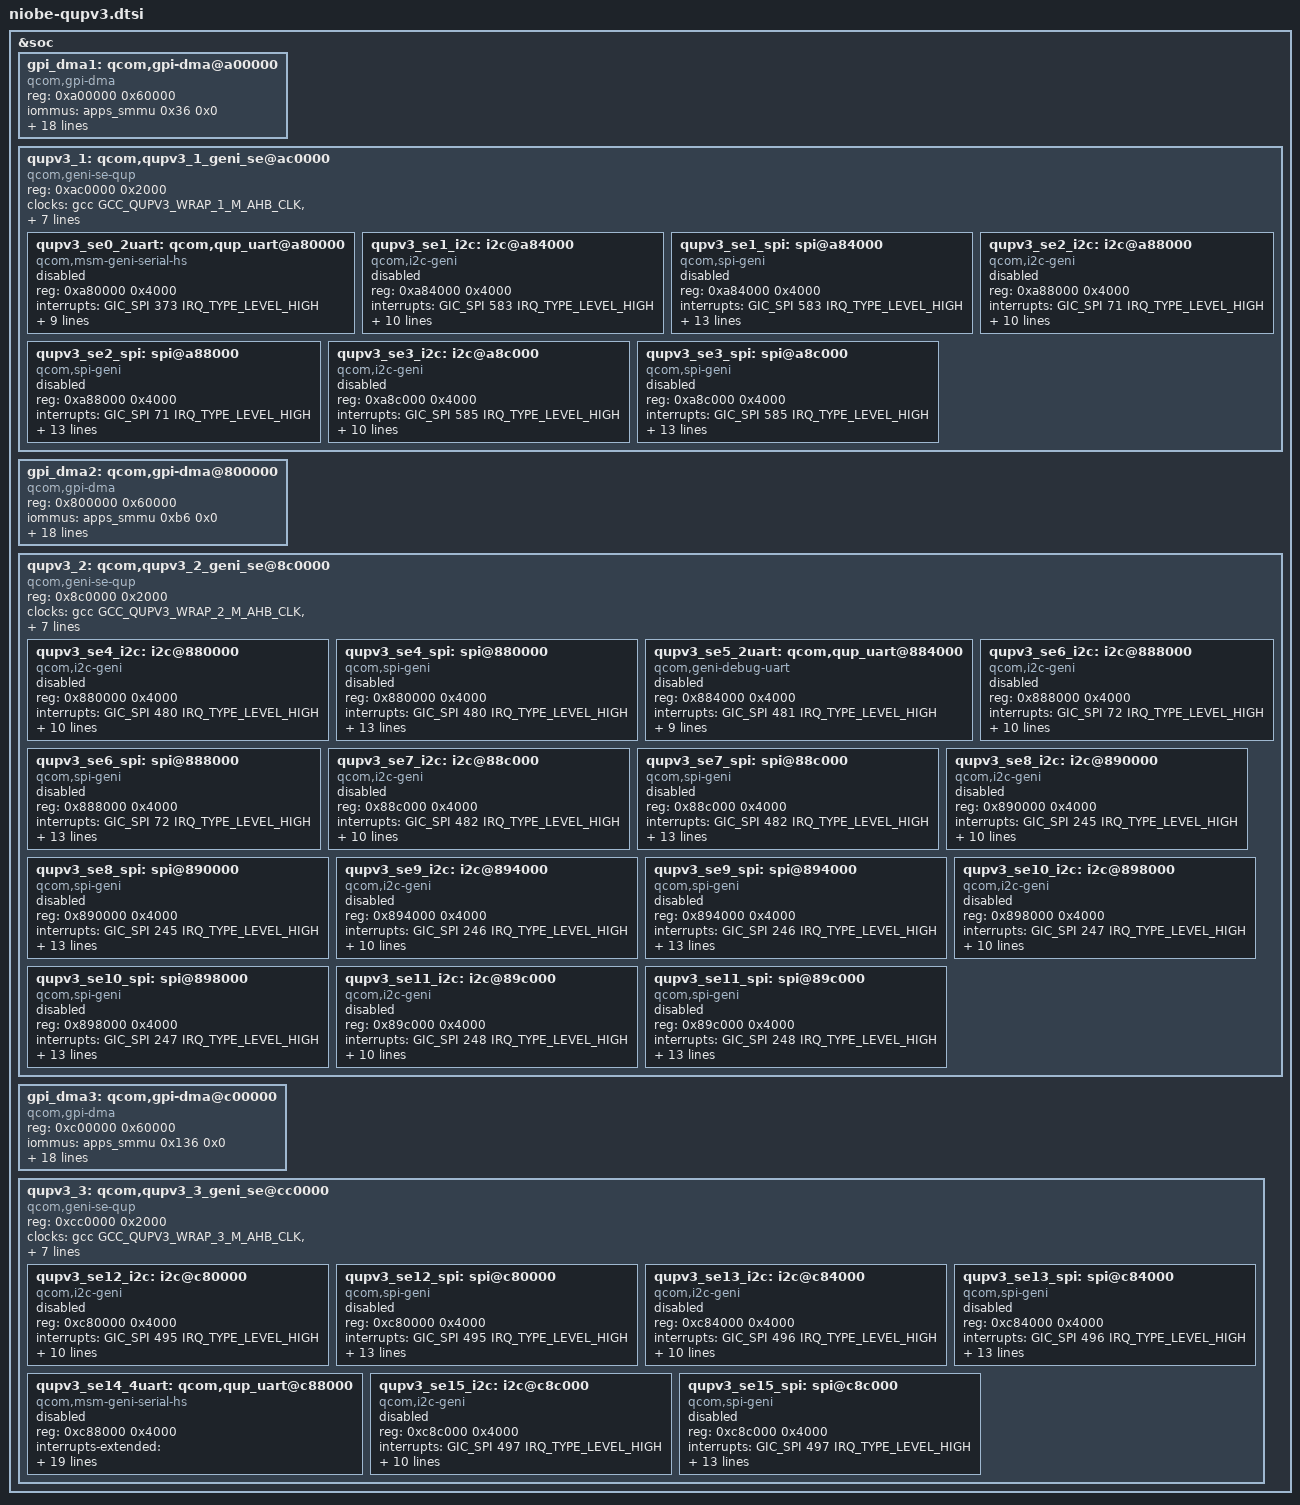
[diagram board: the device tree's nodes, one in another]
&soc {
	/* QUPv3 SE Instances
	 * Qup1 0: SE 0
	 * Qup1 1: SE 1
	 * Qup1 2: SE 2
	 * Qup1 3: SE 3
	 * Qup2 0: SE 4
	 * Qup2 1: SE 5
	 * Qup2 2: SE 6
	 * Qup2 3: SE 7
	 * Qup2 4: SE 8
	 * Qup2 5: SE 9
	 * Qup2 6: SE 10
	 * Qup2 7: SE 11
	 * Qup3 0: SE 12
	 * Qup3 1: SE 13
	 * Qup3 2: SE 14
	 * Qup3 3: SE 15
	 */

	/* GPI Instance */
	gpi_dma1: qcom,gpi-dma@a00000 {
		compatible = "qcom,gpi-dma";
		#dma-cells = <5>;
		reg = <0xa00000 0x60000>;
		reg-names = "gpi-top";
		iommus = <&apps_smmu 0x36 0x0>;
		qcom,max-num-gpii = <12>;
		interrupts = <GIC_SPI 588 IRQ_TYPE_LEVEL_HIGH>,
			<GIC_SPI 589 IRQ_TYPE_LEVEL_HIGH>,
			<GIC_SPI 590 IRQ_TYPE_LEVEL_HIGH>,
			<GIC_SPI 591 IRQ_TYPE_LEVEL_HIGH>,
			<GIC_SPI 592 IRQ_TYPE_LEVEL_HIGH>,
			<GIC_SPI 593 IRQ_TYPE_LEVEL_HIGH>,
			<GIC_SPI 594 IRQ_TYPE_LEVEL_HIGH>,
			<GIC_SPI 595 IRQ_TYPE_LEVEL_HIGH>,
			<GIC_SPI 596 IRQ_TYPE_LEVEL_HIGH>,
			<GIC_SPI 597 IRQ_TYPE_LEVEL_HIGH>,
			<GIC_SPI 598 IRQ_TYPE_LEVEL_HIGH>,
			<GIC_SPI 599 IRQ_TYPE_LEVEL_HIGH>;
		qcom,gpii-mask = <0x3f>;
		qcom,ev-factor = <1>;
		qcom,iommu-dma-addr-pool = <0x100000 0x100000>;
		qcom,gpi-ee-offset = <0x10000>;
		dma-coherent;
		status = "ok";
	};

	/* QUPv3_1  wrapper  instance */
	qupv3_1: qcom,qupv3_1_geni_se@ac0000 {
		compatible = "qcom,geni-se-qup";
		reg = <0xac0000 0x2000>;
		#address-cells = <1>;
		#size-cells = <1>;
		clock-names = "m-ahb", "s-ahb";
		clocks = <&gcc GCC_QUPV3_WRAP_1_M_AHB_CLK>,
			<&gcc GCC_QUPV3_WRAP_1_S_AHB_CLK>;
		iommus = <&apps_smmu 0x23 0x0>;
		qcom,iommu-dma-addr-pool = <0x40000000 0x10000000>;
		qcom,iommu-geometry = <0x40000000 0x10000000>;
		qcom,iommu-dma = "fastmap";
		dma-coherent;
		ranges;
		status = "ok";

		/* Nordic BT UART Instance */
		qupv3_se0_2uart: qcom,qup_uart@a80000 {
			compatible = "qcom,msm-geni-serial-hs";
			reg = <0xa80000 0x4000>;
			reg-names = "se_phys";
			interrupts = <GIC_SPI 373 IRQ_TYPE_LEVEL_HIGH>;
			clock-names = "se-clk";
			clocks = <&gcc GCC_QUPV3_WRAP1_S0_CLK>;
			interconnect-names = "qup-core", "qup-config", "qup-memory";
			interconnects =
			<&clk_virt MASTER_QUP_CORE_1 &clk_virt SLAVE_QUP_CORE_1>,
			<&gem_noc MASTER_APPSS_PROC &cnoc_cfg SLAVE_QUP_1>,
			<&aggre1_noc MASTER_QUP_1 &mc_virt SLAVE_EBI1>;
			pinctrl-names = "default", "sleep";
			pinctrl-0 = <&qupv3_se0_2uart_tx_active>, <&qupv3_se0_2uart_rx_active>;
			pinctrl-1 = <&qupv3_se0_2uart_sleep>;
			status = "disabled";
		};

		qupv3_se1_i2c: i2c@a84000 {
			compatible = "qcom,i2c-geni";
			reg = <0xa84000 0x4000>;
			#address-cells = <1>;
			#size-cells = <0>;
			interrupts = <GIC_SPI 583 IRQ_TYPE_LEVEL_HIGH>;
			clock-names = "se-clk";
			clocks = <&gcc GCC_QUPV3_WRAP1_S1_CLK>;
			interconnect-names = "qup-core", "qup-config", "qup-memory";
			interconnects =
			<&clk_virt MASTER_QUP_CORE_1 &clk_virt SLAVE_QUP_CORE_1>,
			<&gem_noc MASTER_APPSS_PROC &cnoc_cfg SLAVE_QUP_1>,
			<&aggre1_noc MASTER_QUP_1 &mc_virt SLAVE_EBI1>;
			pinctrl-names = "default", "sleep";
			pinctrl-0 = <&qupv3_se1_i2c_sda_active>, <&qupv3_se1_i2c_scl_active>;
			pinctrl-1 = <&qupv3_se1_i2c_sleep>;
			dmas = <&gpi_dma1 0 1 3 64 0>,
				<&gpi_dma1 1 1 3 64 0>;
			dma-names = "tx", "rx";
			status = "disabled";
		};

		qupv3_se1_spi: spi@a84000 {
			compatible = "qcom,spi-geni";
			reg = <0xa84000 0x4000>;
			#address-cells = <1>;
			#size-cells = <0>;
			reg-names = "se_phys";
			interrupts = <GIC_SPI 583 IRQ_TYPE_LEVEL_HIGH>;
			clock-names = "se-clk";
			clocks = <&gcc GCC_QUPV3_WRAP1_S1_CLK>;
			interconnect-names = "qup-core", "qup-config", "qup-memory";
			interconnects =
			<&clk_virt MASTER_QUP_CORE_1 &clk_virt SLAVE_QUP_CORE_1>,
			<&gem_noc MASTER_APPSS_PROC &cnoc_cfg SLAVE_QUP_1>,
			<&aggre1_noc MASTER_QUP_1 &mc_virt SLAVE_EBI1>;
			pinctrl-names = "default", "sleep";
			pinctrl-0 = <&qupv3_se1_spi_mosi_active>, <&qupv3_se1_spi_miso_active>,
				<&qupv3_se1_spi_clk_active>, <&qupv3_se1_spi_cs_active>;
			pinctrl-1 = <&qupv3_se1_spi_sleep>;
			dmas = <&gpi_dma1 0 1 1 64 0>,
				<&gpi_dma1 1 1 1 64 0>;
			dma-names = "tx", "rx";
			spi-max-frequency = <50000000>;
			status = "disabled";
		};

		qupv3_se2_i2c: i2c@a88000 {
			compatible = "qcom,i2c-geni";
			reg = <0xa88000 0x4000>;
			#address-cells = <1>;
			#size-cells = <0>;
			interrupts = <GIC_SPI 71 IRQ_TYPE_LEVEL_HIGH>;
			clock-names = "se-clk";
			clocks = <&gcc GCC_QUPV3_WRAP1_S2_CLK>;
			interconnect-names = "qup-core", "qup-config", "qup-memory";
			interconnects =
			<&clk_virt MASTER_QUP_CORE_1 &clk_virt SLAVE_QUP_CORE_1>,
			<&gem_noc MASTER_APPSS_PROC &cnoc_cfg SLAVE_QUP_1>,
			<&aggre1_noc MASTER_QUP_1 &mc_virt SLAVE_EBI1>;
			pinctrl-names = "default", "sleep";
			pinctrl-0 = <&qupv3_se2_i2c_sda_active>, <&qupv3_se2_i2c_scl_active>;
			pinctrl-1 = <&qupv3_se2_i2c_sleep>;
			dmas = <&gpi_dma1 0 2 3 64 0>,
				<&gpi_dma1 1 2 3 64 0>;
			dma-names = "tx", "rx";
			status = "disabled";
		};

		qupv3_se2_spi: spi@a88000 {
			compatible = "qcom,spi-geni";
			reg = <0xa88000 0x4000>;
			#address-cells = <1>;
			#size-cells = <0>;
			reg-names = "se_phys";
			interrupts = <GIC_SPI 71 IRQ_TYPE_LEVEL_HIGH>;
			clock-names = "se-clk";
			clocks = <&gcc GCC_QUPV3_WRAP1_S2_CLK>;
			interconnect-names = "qup-core", "qup-config", "qup-memory";
			interconnects =
			<&clk_virt MASTER_QUP_CORE_1 &clk_virt SLAVE_QUP_CORE_1>,
			<&gem_noc MASTER_APPSS_PROC &cnoc_cfg SLAVE_QUP_1>,
			<&aggre1_noc MASTER_QUP_1 &mc_virt SLAVE_EBI1>;
			pinctrl-names = "default", "sleep";
			pinctrl-0 = <&qupv3_se2_spi_mosi_active>, <&qupv3_se2_spi_miso_active>,
				<&qupv3_se2_spi_clk_active>, <&qupv3_se2_spi_cs_active>;
			pinctrl-1 = <&qupv3_se2_spi_sleep>;
			dmas = <&gpi_dma1 0 2 1 64 0>,
				<&gpi_dma1 1 2 1 64 0>;
			dma-names = "tx", "rx";
			spi-max-frequency = <50000000>;
			status = "disabled";
		};

		qupv3_se3_i2c: i2c@a8c000 {
			compatible = "qcom,i2c-geni";
			reg = <0xa8c000 0x4000>;
			#address-cells = <1>;
			#size-cells = <0>;
			interrupts = <GIC_SPI 585 IRQ_TYPE_LEVEL_HIGH>;
			clock-names = "se-clk";
			clocks = <&gcc GCC_QUPV3_WRAP1_S3_CLK>;
			interconnect-names = "qup-core", "qup-config", "qup-memory";
			interconnects =
			<&clk_virt MASTER_QUP_CORE_1 &clk_virt SLAVE_QUP_CORE_1>,
			<&gem_noc MASTER_APPSS_PROC &cnoc_cfg SLAVE_QUP_1>,
			<&aggre1_noc MASTER_QUP_1 &mc_virt SLAVE_EBI1>;
			pinctrl-names = "default", "sleep";
			pinctrl-0 = <&qupv3_se3_i2c_sda_active>, <&qupv3_se3_i2c_scl_active>;
			pinctrl-1 = <&qupv3_se3_i2c_sleep>;
			dmas = <&gpi_dma1 0 3 3 64 0>,
				<&gpi_dma1 1 3 3 64 0>;
			dma-names = "tx", "rx";
			status = "disabled";
		};

		qupv3_se3_spi: spi@a8c000 {
			compatible = "qcom,spi-geni";
			reg = <0xa8c000 0x4000>;
			#address-cells = <1>;
			#size-cells = <0>;
			reg-names = "se_phys";
			interrupts = <GIC_SPI 585 IRQ_TYPE_LEVEL_HIGH>;
			clock-names = "se-clk";
			clocks = <&gcc GCC_QUPV3_WRAP1_S3_CLK>;
			interconnect-names = "qup-core", "qup-config", "qup-memory";
			interconnects =
			<&clk_virt MASTER_QUP_CORE_1 &clk_virt SLAVE_QUP_CORE_1>,
			<&gem_noc MASTER_APPSS_PROC &cnoc_cfg SLAVE_QUP_1>,
			<&aggre1_noc MASTER_QUP_1 &mc_virt SLAVE_EBI1>;
			pinctrl-names = "default", "sleep";
			pinctrl-0 = <&qupv3_se3_spi_mosi_active>, <&qupv3_se3_spi_miso_active>,
				<&qupv3_se3_spi_clk_active>, <&qupv3_se3_spi_cs_active>;
			pinctrl-1 = <&qupv3_se3_spi_sleep>;
			dmas = <&gpi_dma1 0 3 1 64 0>,
				<&gpi_dma1 1 3 1 64 0>;
			dma-names = "tx", "rx";
			spi-max-frequency = <50000000>;
			status = "disabled";
		};
	};

	/* GPI Instance */
	gpi_dma2: qcom,gpi-dma@800000 {
		compatible = "qcom,gpi-dma";
		#dma-cells = <5>;
		reg = <0x800000 0x60000>;
		reg-names = "gpi-top";
		iommus = <&apps_smmu 0xb6 0x0>;
		qcom,max-num-gpii = <12>;
		interrupts = <GIC_SPI 483 IRQ_TYPE_LEVEL_HIGH>,
			<GIC_SPI 484 IRQ_TYPE_LEVEL_HIGH>,
			<GIC_SPI 485 IRQ_TYPE_LEVEL_HIGH>,
			<GIC_SPI 486 IRQ_TYPE_LEVEL_HIGH>,
			<GIC_SPI 487 IRQ_TYPE_LEVEL_HIGH>,
			<GIC_SPI 488 IRQ_TYPE_LEVEL_HIGH>,
			<GIC_SPI 489 IRQ_TYPE_LEVEL_HIGH>,
			<GIC_SPI 490 IRQ_TYPE_LEVEL_HIGH>,
			<GIC_SPI 491 IRQ_TYPE_LEVEL_HIGH>,
			<GIC_SPI 492 IRQ_TYPE_LEVEL_HIGH>,
			<GIC_SPI 493 IRQ_TYPE_LEVEL_HIGH>,
			<GIC_SPI 494 IRQ_TYPE_LEVEL_HIGH>;
		qcom,gpii-mask = <0x3f>;
		qcom,ev-factor = <1>;
		qcom,iommu-dma-addr-pool = <0x100000 0x100000>;
		qcom,gpi-ee-offset = <0x10000>;
		dma-coherent;
		status = "ok";
	};

	/* QUPv3_2  wrapper  instance */
	qupv3_2: qcom,qupv3_2_geni_se@8c0000 {
		compatible = "qcom,geni-se-qup";
		reg = <0x8c0000 0x2000>;
		#address-cells = <1>;
		#size-cells = <1>;
		clock-names = "m-ahb", "s-ahb";
		clocks = <&gcc GCC_QUPV3_WRAP_2_M_AHB_CLK>,
			<&gcc GCC_QUPV3_WRAP_2_S_AHB_CLK>;
		iommus = <&apps_smmu 0xa3 0x0>;
		qcom,iommu-dma-addr-pool = <0x40000000 0x10000000>;
		qcom,iommu-geometry = <0x40000000 0x10000000>;
		qcom,iommu-dma = "fastmap";
		dma-coherent;
		ranges;
		status = "ok";

		qupv3_se4_i2c: i2c@880000 {
			compatible = "qcom,i2c-geni";
			reg = <0x880000 0x4000>;
			#address-cells = <1>;
			#size-cells = <0>;
			interrupts = <GIC_SPI 480 IRQ_TYPE_LEVEL_HIGH>;
			clock-names = "se-clk";
			clocks = <&gcc GCC_QUPV3_WRAP2_S0_CLK>;
			interconnect-names = "qup-core", "qup-config", "qup-memory";
			interconnects =
			<&clk_virt MASTER_QUP_CORE_2 &clk_virt SLAVE_QUP_CORE_2>,
			<&gem_noc MASTER_APPSS_PROC &cnoc_cfg SLAVE_QUP_2>,
			<&aggre1_noc MASTER_QUP_2 &mc_virt SLAVE_EBI1>;
			pinctrl-names = "default", "sleep";
			pinctrl-0 = <&qupv3_se4_i2c_sda_active>, <&qupv3_se4_i2c_scl_active>;
			pinctrl-1 = <&qupv3_se4_i2c_sleep>;
			dmas = <&gpi_dma2 0 0 3 64 0>,
				<&gpi_dma2 1 0 3 64 0>;
			dma-names = "tx", "rx";
			status = "disabled";
		};

		qupv3_se4_spi: spi@880000 {
			compatible = "qcom,spi-geni";
			reg = <0x880000 0x4000>;
			#address-cells = <1>;
			#size-cells = <0>;
			reg-names = "se_phys";
			interrupts = <GIC_SPI 480 IRQ_TYPE_LEVEL_HIGH>;
			clock-names = "se-clk";
			clocks = <&gcc GCC_QUPV3_WRAP2_S0_CLK>;
			interconnect-names = "qup-core", "qup-config", "qup-memory";
			interconnects =
			<&clk_virt MASTER_QUP_CORE_2 &clk_virt SLAVE_QUP_CORE_2>,
			<&gem_noc MASTER_APPSS_PROC &cnoc_cfg SLAVE_QUP_2>,
			<&aggre1_noc MASTER_QUP_2 &mc_virt SLAVE_EBI1>;
			pinctrl-names = "default", "sleep";
			pinctrl-0 = <&qupv3_se4_spi_mosi_active>, <&qupv3_se4_spi_miso_active>,
				<&qupv3_se4_spi_clk_active>, <&qupv3_se4_spi_cs_active>;
			pinctrl-1 = <&qupv3_se4_spi_sleep>;
			dmas = <&gpi_dma2 0 0 1 64 0>,
				<&gpi_dma2 1 0 1 64 0>;
			dma-names = "tx", "rx";
			spi-max-frequency = <50000000>;
			status = "disabled";
		};

		/* Debug UART Instance */
		qupv3_se5_2uart: qcom,qup_uart@884000 {
			compatible = "qcom,geni-debug-uart";
			reg = <0x884000 0x4000>;
			reg-names = "se_phys";
			interrupts = <GIC_SPI 481 IRQ_TYPE_LEVEL_HIGH>;
			clock-names = "se";
			clocks = <&gcc GCC_QUPV3_WRAP2_S1_CLK>;
			interconnect-names = "qup-core", "qup-config", "qup-memory";
			interconnects =
			<&clk_virt MASTER_QUP_CORE_2 &clk_virt SLAVE_QUP_CORE_2>,
			<&gem_noc MASTER_APPSS_PROC &cnoc_cfg SLAVE_QUP_2>,
			<&aggre1_noc MASTER_QUP_2 &mc_virt SLAVE_EBI1>;
			pinctrl-names = "default", "sleep";
			pinctrl-0 = <&qupv3_se5_2uart_tx_active>, <&qupv3_se5_2uart_rx_active>;
			pinctrl-1 = <&qupv3_se5_2uart_sleep>;
			status = "disabled";
		};

		qupv3_se6_i2c: i2c@888000 {
			compatible = "qcom,i2c-geni";
			reg = <0x888000 0x4000>;
			#address-cells = <1>;
			#size-cells = <0>;
			interrupts = <GIC_SPI 72 IRQ_TYPE_LEVEL_HIGH>;
			clock-names = "se-clk";
			clocks = <&gcc GCC_QUPV3_WRAP2_S2_CLK>;
			interconnect-names = "qup-core", "qup-config", "qup-memory";
			interconnects =
			<&clk_virt MASTER_QUP_CORE_2 &clk_virt SLAVE_QUP_CORE_2>,
			<&gem_noc MASTER_APPSS_PROC &cnoc_cfg SLAVE_QUP_2>,
			<&aggre1_noc MASTER_QUP_2 &mc_virt SLAVE_EBI1>;
			pinctrl-names = "default", "sleep";
			pinctrl-0 = <&qupv3_se6_i2c_sda_active>, <&qupv3_se6_i2c_scl_active>;
			pinctrl-1 = <&qupv3_se6_i2c_sleep>;
			dmas = <&gpi_dma2 0 2 3 64 0>,
				<&gpi_dma2 1 2 3 64 0>;
			dma-names = "tx", "rx";
			status = "disabled";
		};

		qupv3_se6_spi: spi@888000 {
			compatible = "qcom,spi-geni";
			reg = <0x888000 0x4000>;
			#address-cells = <1>;
			#size-cells = <0>;
			reg-names = "se_phys";
			interrupts = <GIC_SPI 72 IRQ_TYPE_LEVEL_HIGH>;
			clock-names = "se-clk";
			clocks = <&gcc GCC_QUPV3_WRAP2_S2_CLK>;
			interconnect-names = "qup-core", "qup-config", "qup-memory";
			interconnects =
			<&clk_virt MASTER_QUP_CORE_2 &clk_virt SLAVE_QUP_CORE_2>,
			<&gem_noc MASTER_APPSS_PROC &cnoc_cfg SLAVE_QUP_2>,
			<&aggre1_noc MASTER_QUP_2 &mc_virt SLAVE_EBI1>;
			pinctrl-names = "default", "sleep";
			pinctrl-0 = <&qupv3_se6_spi_mosi_active>, <&qupv3_se6_spi_miso_active>,
				<&qupv3_se6_spi_clk_active>, <&qupv3_se6_spi_cs_active>;
			pinctrl-1 = <&qupv3_se6_spi_sleep>;
			dmas = <&gpi_dma2 0 2 1 64 0>,
				<&gpi_dma2 1 2 1 64 0>;
			dma-names = "tx", "rx";
			spi-max-frequency = <50000000>;
			status = "disabled";
		};

		qupv3_se7_i2c: i2c@88c000 {
			compatible = "qcom,i2c-geni";
			reg = <0x88c000 0x4000>;
			#address-cells = <1>;
			#size-cells = <0>;
			interrupts = <GIC_SPI 482 IRQ_TYPE_LEVEL_HIGH>;
			clock-names = "se-clk";
			clocks = <&gcc GCC_QUPV3_WRAP2_S3_CLK>;
			interconnect-names = "qup-core", "qup-config", "qup-memory";
			interconnects =
			<&clk_virt MASTER_QUP_CORE_2 &clk_virt SLAVE_QUP_CORE_2>,
			<&gem_noc MASTER_APPSS_PROC &cnoc_cfg SLAVE_QUP_2>,
			<&aggre1_noc MASTER_QUP_2 &mc_virt SLAVE_EBI1>;
			pinctrl-names = "default", "sleep";
			pinctrl-0 = <&qupv3_se7_i2c_sda_active>, <&qupv3_se7_i2c_scl_active>;
			pinctrl-1 = <&qupv3_se7_i2c_sleep>;
			dmas = <&gpi_dma2 0 3 3 64 0>,
				<&gpi_dma2 1 3 3 64 0>;
			dma-names = "tx", "rx";
			status = "disabled";
		};

		qupv3_se7_spi: spi@88c000 {
			compatible = "qcom,spi-geni";
			reg = <0x88c000 0x4000>;
			#address-cells = <1>;
			#size-cells = <0>;
			reg-names = "se_phys";
			interrupts = <GIC_SPI 482 IRQ_TYPE_LEVEL_HIGH>;
			clock-names = "se-clk";
			clocks = <&gcc GCC_QUPV3_WRAP2_S3_CLK>;
			interconnect-names = "qup-core", "qup-config", "qup-memory";
			interconnects =
			<&clk_virt MASTER_QUP_CORE_2 &clk_virt SLAVE_QUP_CORE_2>,
			<&gem_noc MASTER_APPSS_PROC &cnoc_cfg SLAVE_QUP_2>,
			<&aggre1_noc MASTER_QUP_2 &mc_virt SLAVE_EBI1>;
			pinctrl-names = "default", "sleep";
			pinctrl-0 = <&qupv3_se7_spi_mosi_active>, <&qupv3_se7_spi_miso_active>,
				<&qupv3_se7_spi_clk_active>, <&qupv3_se7_spi_cs_active>;
			pinctrl-1 = <&qupv3_se7_spi_sleep>;
			dmas = <&gpi_dma2 0 3 1 64 0>,
				<&gpi_dma2 1 3 1 64 0>;
			dma-names = "tx", "rx";
			spi-max-frequency = <50000000>;
			status = "disabled";
		};

		qupv3_se8_i2c: i2c@890000 {
			compatible = "qcom,i2c-geni";
			reg = <0x890000 0x4000>;
			#address-cells = <1>;
			#size-cells = <0>;
			interrupts = <GIC_SPI 245 IRQ_TYPE_LEVEL_HIGH>;
			clock-names = "se-clk";
			clocks = <&gcc GCC_QUPV3_WRAP2_S4_CLK>;
			interconnect-names = "qup-core", "qup-config", "qup-memory";
			interconnects =
			<&clk_virt MASTER_QUP_CORE_2 &clk_virt SLAVE_QUP_CORE_2>,
			<&gem_noc MASTER_APPSS_PROC &cnoc_cfg SLAVE_QUP_2>,
			<&aggre1_noc MASTER_QUP_2 &mc_virt SLAVE_EBI1>;
			pinctrl-names = "default", "sleep";
			pinctrl-0 = <&qupv3_se8_i2c_sda_active>, <&qupv3_se8_i2c_scl_active>;
			pinctrl-1 = <&qupv3_se8_i2c_sleep>;
			dmas = <&gpi_dma2 0 4 3 64 0>,
				<&gpi_dma2 1 4 3 64 0>;
			dma-names = "tx", "rx";
			status = "disabled";
		};

		qupv3_se8_spi: spi@890000 {
			compatible = "qcom,spi-geni";
			reg = <0x890000 0x4000>;
			#address-cells = <1>;
			#size-cells = <0>;
			reg-names = "se_phys";
			interrupts = <GIC_SPI 245 IRQ_TYPE_LEVEL_HIGH>;
			clock-names = "se-clk";
			clocks = <&gcc GCC_QUPV3_WRAP2_S4_CLK>;
			interconnect-names = "qup-core", "qup-config", "qup-memory";
			interconnects =
			<&clk_virt MASTER_QUP_CORE_2 &clk_virt SLAVE_QUP_CORE_2>,
			<&gem_noc MASTER_APPSS_PROC &cnoc_cfg SLAVE_QUP_2>,
			<&aggre1_noc MASTER_QUP_2 &mc_virt SLAVE_EBI1>;
			pinctrl-names = "default", "sleep";
			pinctrl-0 = <&qupv3_se8_spi_mosi_active>, <&qupv3_se8_spi_miso_active>,
				<&qupv3_se8_spi_clk_active>, <&qupv3_se8_spi_cs_active>;
			pinctrl-1 = <&qupv3_se8_spi_sleep>;
			dmas = <&gpi_dma2 0 4 1 64 0>,
				<&gpi_dma2 1 4 1 64 0>;
			dma-names = "tx", "rx";
			spi-max-frequency = <50000000>;
			status = "disabled";
		};

		qupv3_se9_i2c: i2c@894000 {
			compatible = "qcom,i2c-geni";
			reg = <0x894000 0x4000>;
			#address-cells = <1>;
			#size-cells = <0>;
			interrupts = <GIC_SPI 246 IRQ_TYPE_LEVEL_HIGH>;
			clock-names = "se-clk";
			clocks = <&gcc GCC_QUPV3_WRAP2_S5_CLK>;
			interconnect-names = "qup-core", "qup-config", "qup-memory";
			interconnects =
			<&clk_virt MASTER_QUP_CORE_2 &clk_virt SLAVE_QUP_CORE_2>,
			<&gem_noc MASTER_APPSS_PROC &cnoc_cfg SLAVE_QUP_2>,
			<&aggre1_noc MASTER_QUP_2 &mc_virt SLAVE_EBI1>;
			pinctrl-names = "default", "sleep";
			pinctrl-0 = <&qupv3_se9_i2c_sda_active>, <&qupv3_se9_i2c_scl_active>;
			pinctrl-1 = <&qupv3_se9_i2c_sleep>;
			dmas = <&gpi_dma2 0 5 3 64 0>,
				<&gpi_dma2 1 5 3 64 0>;
			dma-names = "tx", "rx";
			status = "disabled";
		};

		qupv3_se9_spi: spi@894000 {
			compatible = "qcom,spi-geni";
			reg = <0x894000 0x4000>;
			#address-cells = <1>;
			#size-cells = <0>;
			reg-names = "se_phys";
			interrupts = <GIC_SPI 246 IRQ_TYPE_LEVEL_HIGH>;
			clock-names = "se-clk";
			clocks = <&gcc GCC_QUPV3_WRAP2_S5_CLK>;
			interconnect-names = "qup-core", "qup-config", "qup-memory";
			interconnects =
			<&clk_virt MASTER_QUP_CORE_2 &clk_virt SLAVE_QUP_CORE_2>,
			<&gem_noc MASTER_APPSS_PROC &cnoc_cfg SLAVE_QUP_2>,
			<&aggre1_noc MASTER_QUP_2 &mc_virt SLAVE_EBI1>;
			pinctrl-names = "default", "sleep";
			pinctrl-0 = <&qupv3_se9_spi_mosi_active>, <&qupv3_se9_spi_miso_active>,
				<&qupv3_se9_spi_clk_active>, <&qupv3_se9_spi_cs_active>;
			pinctrl-1 = <&qupv3_se9_spi_sleep>;
			dmas = <&gpi_dma2 0 5 1 64 0>,
				<&gpi_dma2 1 5 1 64 0>;
			dma-names = "tx", "rx";
			spi-max-frequency = <50000000>;
			status = "disabled";
		};

		qupv3_se10_i2c: i2c@898000 {
			compatible = "qcom,i2c-geni";
			reg = <0x898000 0x4000>;
			#address-cells = <1>;
			#size-cells = <0>;
			interrupts = <GIC_SPI 247 IRQ_TYPE_LEVEL_HIGH>;
			clock-names = "se-clk";
			clocks = <&gcc GCC_QUPV3_WRAP2_S6_CLK>;
			interconnect-names = "qup-core", "qup-config", "qup-memory";
			interconnects =
			<&clk_virt MASTER_QUP_CORE_2 &clk_virt SLAVE_QUP_CORE_2>,
			<&gem_noc MASTER_APPSS_PROC &cnoc_cfg SLAVE_QUP_2>,
			<&aggre1_noc MASTER_QUP_2 &mc_virt SLAVE_EBI1>;
			pinctrl-names = "default", "sleep";
			pinctrl-0 = <&qupv3_se10_i2c_sda_active>, <&qupv3_se10_i2c_scl_active>;
			pinctrl-1 = <&qupv3_se10_i2c_sleep>;
			dmas = <&gpi_dma2 0 6 3 64 0>,
				<&gpi_dma2 1 6 3 64 0>;
			dma-names = "tx", "rx";
			status = "disabled";
		};

		qupv3_se10_spi: spi@898000 {
			compatible = "qcom,spi-geni";
			reg = <0x898000 0x4000>;
			#address-cells = <1>;
			#size-cells = <0>;
			reg-names = "se_phys";
			interrupts = <GIC_SPI 247 IRQ_TYPE_LEVEL_HIGH>;
			clock-names = "se-clk";
			clocks = <&gcc GCC_QUPV3_WRAP2_S6_CLK>;
			interconnect-names = "qup-core", "qup-config", "qup-memory";
			interconnects =
			<&clk_virt MASTER_QUP_CORE_2 &clk_virt SLAVE_QUP_CORE_2>,
			<&gem_noc MASTER_APPSS_PROC &cnoc_cfg SLAVE_QUP_2>,
			<&aggre1_noc MASTER_QUP_2 &mc_virt SLAVE_EBI1>;
			pinctrl-names = "default", "sleep";
			pinctrl-0 = <&qupv3_se10_spi_mosi_active>, <&qupv3_se10_spi_miso_active>,
				<&qupv3_se10_spi_clk_active>, <&qupv3_se10_spi_cs_active>;
			pinctrl-1 = <&qupv3_se10_spi_sleep>;
			dmas = <&gpi_dma2 0 6 1 64 0>,
				<&gpi_dma2 1 6 1 64 0>;
			dma-names = "tx", "rx";
			spi-max-frequency = <50000000>;
			status = "disabled";
		};

		qupv3_se11_i2c: i2c@89c000 {
			compatible = "qcom,i2c-geni";
			reg = <0x89c000 0x4000>;
			#address-cells = <1>;
			#size-cells = <0>;
			interrupts = <GIC_SPI 248 IRQ_TYPE_LEVEL_HIGH>;
			clock-names = "se-clk";
			clocks = <&gcc GCC_QUPV3_WRAP2_S7_CLK>;
			interconnect-names = "qup-core", "qup-config", "qup-memory";
			interconnects =
			<&clk_virt MASTER_QUP_CORE_2 &clk_virt SLAVE_QUP_CORE_2>,
			<&gem_noc MASTER_APPSS_PROC &cnoc_cfg SLAVE_QUP_2>,
			<&aggre1_noc MASTER_QUP_2 &mc_virt SLAVE_EBI1>;
			pinctrl-names = "default", "sleep";
			pinctrl-0 = <&qupv3_se11_i2c_sda_active>, <&qupv3_se11_i2c_scl_active>;
			pinctrl-1 = <&qupv3_se11_i2c_sleep>;
			dmas = <&gpi_dma2 0 7 3 64 0>,
				<&gpi_dma2 1 7 3 64 0>;
			dma-names = "tx", "rx";
			status = "disabled";
		};

		qupv3_se11_spi: spi@89c000 {
			compatible = "qcom,spi-geni";
			reg = <0x89c000 0x4000>;
			#address-cells = <1>;
			#size-cells = <0>;
			reg-names = "se_phys";
			interrupts = <GIC_SPI 248 IRQ_TYPE_LEVEL_HIGH>;
			clock-names = "se-clk";
			clocks = <&gcc GCC_QUPV3_WRAP2_S7_CLK>;
			interconnect-names = "qup-core", "qup-config", "qup-memory";
			interconnects =
			<&clk_virt MASTER_QUP_CORE_2 &clk_virt SLAVE_QUP_CORE_2>,
			<&gem_noc MASTER_APPSS_PROC &cnoc_cfg SLAVE_QUP_2>,
			<&aggre1_noc MASTER_QUP_2 &mc_virt SLAVE_EBI1>;
			pinctrl-names = "default", "sleep";
			pinctrl-0 = <&qupv3_se11_spi_mosi_active>, <&qupv3_se11_spi_miso_active>,
				<&qupv3_se11_spi_clk_active>, <&qupv3_se11_spi_cs_active>;
			pinctrl-1 = <&qupv3_se11_spi_sleep>;
			dmas = <&gpi_dma2 0 7 1 64 0>,
				<&gpi_dma2 1 7 1 64 0>;
			dma-names = "tx", "rx";
			spi-max-frequency = <50000000>;
			status = "disabled";
		};
	};

	/* GPI Instance */
	gpi_dma3: qcom,gpi-dma@c00000 {
		compatible = "qcom,gpi-dma";
		#dma-cells = <5>;
		reg = <0xc00000 0x60000>;
		reg-names = "gpi-top";
		iommus = <&apps_smmu 0x136 0x0>;
		qcom,max-num-gpii = <12>;
		interrupts = <GIC_SPI 498 IRQ_TYPE_LEVEL_HIGH>,
			<GIC_SPI 499 IRQ_TYPE_LEVEL_HIGH>,
			<GIC_SPI 500 IRQ_TYPE_LEVEL_HIGH>,
			<GIC_SPI 501 IRQ_TYPE_LEVEL_HIGH>,
			<GIC_SPI 502 IRQ_TYPE_LEVEL_HIGH>,
			<GIC_SPI 503 IRQ_TYPE_LEVEL_HIGH>,
			<GIC_SPI 504 IRQ_TYPE_LEVEL_HIGH>,
			<GIC_SPI 505 IRQ_TYPE_LEVEL_HIGH>,
			<GIC_SPI 506 IRQ_TYPE_LEVEL_HIGH>,
			<GIC_SPI 507 IRQ_TYPE_LEVEL_HIGH>,
			<GIC_SPI 508 IRQ_TYPE_LEVEL_HIGH>,
			<GIC_SPI 509 IRQ_TYPE_LEVEL_HIGH>;
		qcom,gpii-mask = <0x3f>;
		qcom,ev-factor = <1>;
		qcom,iommu-dma-addr-pool = <0x100000 0x100000>;
		qcom,gpi-ee-offset = <0x10000>;
		dma-coherent;
		status = "ok";
	};

	/* QUPv3_3  wrapper  instance */
	qupv3_3: qcom,qupv3_3_geni_se@cc0000 {
		compatible = "qcom,geni-se-qup";
		reg = <0xcc0000 0x2000>;
		#address-cells = <1>;
		#size-cells = <1>;
		clock-names = "m-ahb", "s-ahb";
		clocks = <&gcc GCC_QUPV3_WRAP_3_M_AHB_CLK>,
			<&gcc GCC_QUPV3_WRAP_3_S_AHB_CLK>;
		iommus = <&apps_smmu 0x123 0x0>;
		qcom,iommu-dma-addr-pool = <0x40000000 0x10000000>;
		qcom,iommu-geometry = <0x40000000 0x10000000>;
		qcom,iommu-dma = "fastmap";
		dma-coherent;
		ranges;
		status = "ok";

		qupv3_se12_i2c: i2c@c80000 {
			compatible = "qcom,i2c-geni";
			reg = <0xc80000 0x4000>;
			#address-cells = <1>;
			#size-cells = <0>;
			interrupts = <GIC_SPI 495 IRQ_TYPE_LEVEL_HIGH>;
			clock-names = "se-clk";
			clocks = <&gcc GCC_QUPV3_WRAP3_S0_CLK>;
			interconnect-names = "qup-core", "qup-config", "qup-memory";
			interconnects =
			<&clk_virt MASTER_QUP_CORE_3 &clk_virt SLAVE_QUP_CORE_3>,
			<&gem_noc MASTER_APPSS_PROC &cnoc_cfg SLAVE_QUP_3>,
			<&aggre1_noc MASTER_QUP_3 &mc_virt SLAVE_EBI1>;
			pinctrl-names = "default", "sleep";
			pinctrl-0 = <&qupv3_se12_i2c_sda_active>, <&qupv3_se12_i2c_scl_active>;
			pinctrl-1 = <&qupv3_se12_i2c_sleep>;
			dmas = <&gpi_dma3 0 0 3 64 0>,
				<&gpi_dma3 1 0 3 64 0>;
			dma-names = "tx", "rx";
			status = "disabled";
		};

		qupv3_se12_spi: spi@c80000 {
			compatible = "qcom,spi-geni";
			reg = <0xc80000 0x4000>;
			#address-cells = <1>;
			#size-cells = <0>;
			reg-names = "se_phys";
			interrupts = <GIC_SPI 495 IRQ_TYPE_LEVEL_HIGH>;
			clock-names = "se-clk";
			clocks = <&gcc GCC_QUPV3_WRAP3_S0_CLK>;
			interconnect-names = "qup-core", "qup-config", "qup-memory";
			interconnects =
			<&clk_virt MASTER_QUP_CORE_3 &clk_virt SLAVE_QUP_CORE_3>,
			<&gem_noc MASTER_APPSS_PROC &cnoc_cfg SLAVE_QUP_3>,
			<&aggre1_noc MASTER_QUP_3 &mc_virt SLAVE_EBI1>;
			pinctrl-names = "default", "sleep";
			pinctrl-0 = <&qupv3_se12_spi_mosi_active>, <&qupv3_se12_spi_miso_active>,
				<&qupv3_se12_spi_clk_active>, <&qupv3_se12_spi_cs_active>;
			pinctrl-1 = <&qupv3_se12_spi_sleep>;
			dmas = <&gpi_dma3 0 0 1 64 0>,
				<&gpi_dma3 1 0 1 64 0>;
			dma-names = "tx", "rx";
			spi-max-frequency = <50000000>;
			status = "disabled";
		};

		qupv3_se13_i2c: i2c@c84000 {
			compatible = "qcom,i2c-geni";
			reg = <0xc84000 0x4000>;
			#address-cells = <1>;
			#size-cells = <0>;
			interrupts = <GIC_SPI 496 IRQ_TYPE_LEVEL_HIGH>;
			clock-names = "se-clk";
			clocks = <&gcc GCC_QUPV3_WRAP3_S1_CLK>;
			interconnect-names = "qup-core", "qup-config", "qup-memory";
			interconnects =
			<&clk_virt MASTER_QUP_CORE_3 &clk_virt SLAVE_QUP_CORE_3>,
			<&gem_noc MASTER_APPSS_PROC &cnoc_cfg SLAVE_QUP_3>,
			<&aggre1_noc MASTER_QUP_3 &mc_virt SLAVE_EBI1>;
			pinctrl-names = "default", "sleep";
			pinctrl-0 = <&qupv3_se13_i2c_sda_active>, <&qupv3_se13_i2c_scl_active>;
			pinctrl-1 = <&qupv3_se13_i2c_sleep>;
			dmas = <&gpi_dma3 0 1 3 64 0>,
				<&gpi_dma3 1 1 3 64 0>;
			dma-names = "tx", "rx";
			status = "disabled";
		};

		qupv3_se13_spi: spi@c84000 {
			compatible = "qcom,spi-geni";
			reg = <0xc84000 0x4000>;
			#address-cells = <1>;
			#size-cells = <0>;
			reg-names = "se_phys";
			interrupts = <GIC_SPI 496 IRQ_TYPE_LEVEL_HIGH>;
			clock-names = "se-clk";
			clocks = <&gcc GCC_QUPV3_WRAP3_S1_CLK>;
			interconnect-names = "qup-core", "qup-config", "qup-memory";
			interconnects =
			<&clk_virt MASTER_QUP_CORE_3 &clk_virt SLAVE_QUP_CORE_3>,
			<&gem_noc MASTER_APPSS_PROC &cnoc_cfg SLAVE_QUP_3>,
			<&aggre1_noc MASTER_QUP_3 &mc_virt SLAVE_EBI1>;
			pinctrl-names = "default", "sleep";
			pinctrl-0 = <&qupv3_se13_spi_mosi_active>, <&qupv3_se13_spi_miso_active>,
				<&qupv3_se13_spi_clk_active>, <&qupv3_se13_spi_cs_active>;
			pinctrl-1 = <&qupv3_se13_spi_sleep>;
			dmas = <&gpi_dma3 0 1 1 64 0>,
				<&gpi_dma3 1 1 1 64 0>;
			dma-names = "tx", "rx";
			spi-max-frequency = <50000000>;
			status = "disabled";
		};

		/* HS UART Instance */
		qupv3_se14_4uart: qcom,qup_uart@c88000 {
			compatible = "qcom,msm-geni-serial-hs";
			reg = <0xc88000 0x4000>;
			reg-names = "se_phys";
			interrupts-extended = <&intc GIC_SPI 73 IRQ_TYPE_LEVEL_HIGH>,
					<&tlmm 47 IRQ_TYPE_LEVEL_HIGH>;
			clock-names = "se-clk";
			clocks = <&gcc GCC_QUPV3_WRAP3_S2_CLK>;
			interconnect-names = "qup-core", "qup-config", "qup-memory";
			interconnects =
			<&clk_virt MASTER_QUP_CORE_3 &clk_virt SLAVE_QUP_CORE_3>,
			<&gem_noc MASTER_APPSS_PROC &cnoc_cfg SLAVE_QUP_3>,
			<&aggre1_noc MASTER_QUP_3 &mc_virt SLAVE_EBI1>;
			pinctrl-names = "default", "active", "sleep", "shutdown";
			pinctrl-0 = <&qupv3_se14_default_cts>, <&qupv3_se14_default_rts>,
			<&qupv3_se14_default_tx>, <&qupv3_se14_default_rx>;
			pinctrl-1 = <&qupv3_se14_cts>, <&qupv3_se14_rts>,
			<&qupv3_se14_tx>, <&qupv3_se14_rx>;
			pinctrl-2 = <&qupv3_se14_cts>, <&qupv3_se14_rts>,
			<&qupv3_se14_tx>, <&qupv3_se14_default_rx>;
			pinctrl-3 = <&qupv3_se14_default_cts>, <&qupv3_se14_default_rts>,
			<&qupv3_se14_default_tx>, <&qupv3_se14_default_rx>;
			qcom,wakeup-byte = <0xFD>;
			status = "disabled";
		};

		qupv3_se15_i2c: i2c@c8c000 {
			compatible = "qcom,i2c-geni";
			reg = <0xc8c000 0x4000>;
			#address-cells = <1>;
			#size-cells = <0>;
			interrupts = <GIC_SPI 497 IRQ_TYPE_LEVEL_HIGH>;
			clock-names = "se-clk";
			clocks = <&gcc GCC_QUPV3_WRAP3_S3_CLK>;
			interconnect-names = "qup-core", "qup-config", "qup-memory";
			interconnects =
			<&clk_virt MASTER_QUP_CORE_3 &clk_virt SLAVE_QUP_CORE_3>,
			<&gem_noc MASTER_APPSS_PROC &cnoc_cfg SLAVE_QUP_3>,
			<&aggre1_noc MASTER_QUP_3 &mc_virt SLAVE_EBI1>;
			pinctrl-names = "default", "sleep";
			pinctrl-0 = <&qupv3_se15_i2c_sda_active>, <&qupv3_se15_i2c_scl_active>;
			pinctrl-1 = <&qupv3_se15_i2c_sleep>;
			dmas = <&gpi_dma3 0 3 3 64 0>,
				<&gpi_dma3 1 3 3 64 0>;
			dma-names = "tx", "rx";
			status = "disabled";
		};

		qupv3_se15_spi: spi@c8c000 {
			compatible = "qcom,spi-geni";
			reg = <0xc8c000 0x4000>;
			#address-cells = <1>;
			#size-cells = <0>;
			reg-names = "se_phys";
			interrupts = <GIC_SPI 497 IRQ_TYPE_LEVEL_HIGH>;
			clock-names = "se-clk";
			clocks = <&gcc GCC_QUPV3_WRAP3_S3_CLK>;
			interconnect-names = "qup-core", "qup-config", "qup-memory";
			interconnects =
			<&clk_virt MASTER_QUP_CORE_3 &clk_virt SLAVE_QUP_CORE_3>,
			<&gem_noc MASTER_APPSS_PROC &cnoc_cfg SLAVE_QUP_3>,
			<&aggre1_noc MASTER_QUP_3 &mc_virt SLAVE_EBI1>;
			pinctrl-names = "default", "sleep";
			pinctrl-0 = <&qupv3_se15_spi_mosi_active>, <&qupv3_se15_spi_miso_active>,
				<&qupv3_se15_spi_clk_active>, <&qupv3_se15_spi_cs_active>;
			pinctrl-1 = <&qupv3_se15_spi_sleep>;
			dmas = <&gpi_dma3 0 3 1 64 0>,
				<&gpi_dma3 1 3 1 64 0>;
			dma-names = "tx", "rx";
			spi-max-frequency = <50000000>;
			status = "disabled";
		};
	};
};
